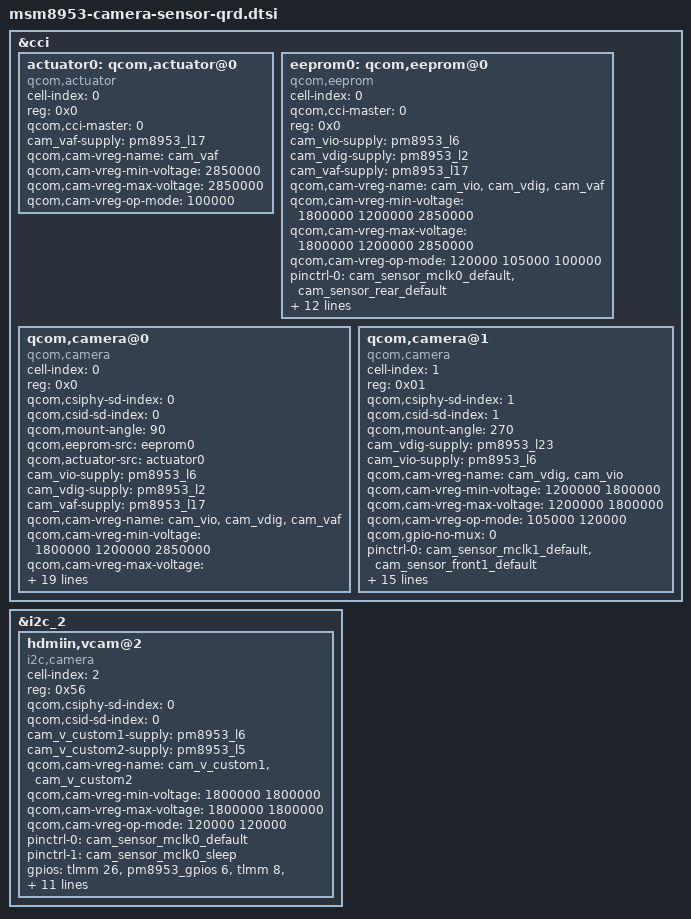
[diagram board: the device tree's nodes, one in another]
/*
 * Copyright (c) 2015-2018, 2021 The Linux Foundation. All rights reserved.
 *
 * This program is free software; you can redistribute it and/or modify
 * it under the terms of the GNU General Public License version 2 and
 * only version 2 as published by the Free Software Foundation.
 *
 * This program is distributed in the hope that it will be useful,
 * but WITHOUT ANY WARRANTY; without even the implied warranty of
 * MERCHANTABILITY or FITNESS FOR A PARTICULAR PURPOSE.  See the
 * GNU General Public License for more details.
 */

&cci {
	#address-cells = <1>;
	#size-cells = <0>;

	actuator0: qcom,actuator@0 {
		cell-index = <0>;
		reg = <0x0>;
		compatible = "qcom,actuator";
		qcom,cci-master = <0>;
		cam_vaf-supply = <&pm8953_l17>;
		qcom,cam-vreg-name = "cam_vaf";
		qcom,cam-vreg-min-voltage = <2850000>;
		qcom,cam-vreg-max-voltage = <2850000>;
		qcom,cam-vreg-op-mode = <100000>;
		status = "ok";
	};

	eeprom0: qcom,eeprom@0 {
		cell-index = <0>;
		compatible = "qcom,eeprom";
		qcom,cci-master = <0>;
		reg = <0x0>;
		cam_vio-supply = <&pm8953_l6>;
		cam_vdig-supply = <&pm8953_l2>;
		cam_vaf-supply = <&pm8953_l17>;
		qcom,cam-vreg-name = "cam_vio", "cam_vdig", "cam_vaf";
		qcom,cam-vreg-min-voltage = <1800000 1200000 2850000>;
		qcom,cam-vreg-max-voltage = <1800000 1200000 2850000>;
		qcom,cam-vreg-op-mode = <120000 105000 100000>;
		pinctrl-names = "cam_default", "cam_suspend";
		pinctrl-0 = <&cam_sensor_mclk0_default
				&cam_sensor_rear_default>;
		pinctrl-1 = <&cam_sensor_mclk0_sleep
				&cam_sensor_rear_sleep>;
		gpios = <&tlmm 26 0>,
			<&tlmm 40 0>,
			<&tlmm 134 0>;
		qcom,gpio-reset = <1>;
		qcom,gpio-standby = <2>;
		qcom,gpio-req-tbl-num = <0 1 2>;
		qcom,gpio-req-tbl-flags = <1 0 0>;
		qcom,gpio-req-tbl-label = "CAMIF_MCLK0",
					"CAM_RESET0",
					"CAM_VANA0";
		status = "ok";
		clocks = <&clock_gcc clk_mclk0_clk_src>,
				<&clock_gcc clk_gcc_camss_mclk0_clk>;
		clock-names = "cam_src_clk", "cam_clk";
		qcom,clock-rates = <24000000 0>;
	};

	qcom,camera@0 {
		cell-index = <0>;
		compatible = "qcom,camera";
		reg = <0x0>;
		qcom,csiphy-sd-index = <0>;
		qcom,csid-sd-index = <0>;
		qcom,mount-angle = <90>;
		qcom,eeprom-src = <&eeprom0>;
		qcom,actuator-src = <&actuator0>;
		cam_vio-supply = <&pm8953_l6>;
		cam_vdig-supply = <&pm8953_l2>;
		cam_vaf-supply = <&pm8953_l17>;
		qcom,cam-vreg-name = "cam_vio", "cam_vdig", "cam_vaf";
		qcom,cam-vreg-min-voltage = <1800000 1200000 2850000>;
		qcom,cam-vreg-max-voltage = <1800000 1200000 2850000>;
		qcom,cam-vreg-op-mode = <120000 105000 100000>;
		pinctrl-names = "cam_default", "cam_suspend";
		pinctrl-0 = <&cam_sensor_mclk0_default
				&cam_sensor_rear_default>;
		pinctrl-1 = <&cam_sensor_mclk0_sleep
				&cam_sensor_rear_sleep>;
		gpios = <&tlmm 26 0>,
			<&tlmm 40 0>,
			<&tlmm 134 0>;
		qcom,gpio-reset = <1>;
		qcom,gpio-vana = <2>;
		qcom,gpio-req-tbl-num = <0 1 2>;
		qcom,gpio-req-tbl-flags = <1 0 0>;
		qcom,gpio-req-tbl-label = "CAMIF_MCLK0",
								"CAM_RESET0",
								"CAM_VANA0";
		qcom,sensor-position = <0>;
		qcom,sensor-mode = <0>;
		qcom,cci-master = <0>;
		status = "ok";
		clocks = <&clock_gcc clk_mclk0_clk_src>,
				<&clock_gcc clk_gcc_camss_mclk0_clk>;
		clock-names = "cam_src_clk", "cam_clk";
		qcom,clock-rates = <24000000 0>;
	};

	qcom,camera@1 {
		cell-index = <1>;
		compatible = "qcom,camera";
		reg = <0x01>;
		qcom,csiphy-sd-index = <1>;
		qcom,csid-sd-index = <1>;
		qcom,mount-angle = <270>;
		cam_vdig-supply = <&pm8953_l23>;
		cam_vio-supply = <&pm8953_l6>;
		qcom,cam-vreg-name = "cam_vdig", "cam_vio";
		qcom,cam-vreg-min-voltage = <1200000 1800000>;
		qcom,cam-vreg-max-voltage = <1200000 1800000>;
		qcom,cam-vreg-op-mode = <105000 120000>;
		qcom,gpio-no-mux = <0>;
		pinctrl-names = "cam_default", "cam_suspend";
		pinctrl-0 = <&cam_sensor_mclk1_default
				&cam_sensor_front1_default>;
		pinctrl-1 = <&cam_sensor_mclk1_sleep
				&cam_sensor_front1_sleep>;
		gpios = <&tlmm 27 0>,
			<&tlmm 129 0>,
			<&tlmm 130 0>;
		qcom,gpio-reset = <1>;
		qcom,gpio-vana = <2>;
		qcom,gpio-req-tbl-num = <0 1 2>;
		qcom,gpio-req-tbl-flags = <1 0 0>;
		qcom,gpio-req-tbl-label = "CAMIF_MCLK1",
								"CAM_RESET1",
								"CAM_VANA1";
		qcom,sensor-position = <1>;
		qcom,sensor-mode = <0>;
		qcom,cci-master = <0>;
		status = "ok";
		clocks = <&clock_gcc clk_mclk1_clk_src>,
			<&clock_gcc clk_gcc_camss_mclk1_clk>;
		clock-names = "cam_src_clk", "cam_clk";
		qcom,clock-rates = <24000000 0>;
	};
};

&i2c_2 {
	status = "ok";
	hdmiin,vcam@2 {
		cell-index = <2>;
		compatible = "i2c,camera";
		reg = <0x56>;
		qcom,csiphy-sd-index = <0>;
		qcom,csid-sd-index = <0>;
		cam_v_custom1-supply = <&pm8953_l6>;
		cam_v_custom2-supply = <&pm8953_l5>;
		qcom,cam-vreg-name = "cam_v_custom1", "cam_v_custom2";
		qcom,cam-vreg-min-voltage = <1800000 1800000>;
		qcom,cam-vreg-max-voltage = <1800000 1800000>;
		qcom,cam-vreg-op-mode = <120000 120000>;
		pinctrl-names = "cam_default", "cam_suspend";
		pinctrl-0 = <&cam_sensor_mclk0_default>;
		pinctrl-1 = <&cam_sensor_mclk0_sleep>;
		gpios = <&tlmm 26 0>,
			<&pm8953_gpios 6 0>,
			<&tlmm 8 0>,
			<&tlmm 128 0>;
		qcom,gpio-reset = <1>;
		qcom,gpio-custom1 = <2>;
		qcom,gpio-custom2 = <3>;
		qcom,gpio-req-tbl-num = <0 1 2 3>;
		qcom,gpio-req-tbl-flags = <1 0 0 0>;
		qcom,gpio-req-tbl-label = "CAMIF_MCLK0",
								"HDMI_RESET0",
								"HDMI_ENABLE1",
								"HDMI_ENABLE2";
		status = "ok";
		clocks = <&clock_gcc clk_mclk0_clk_src>,
				<&clock_gcc clk_gcc_camss_mclk0_clk>;
		clock-names = "cam_src_clk", "cam_clk";
		qcom,clock-rates = <24000000 0>;
	};
};
